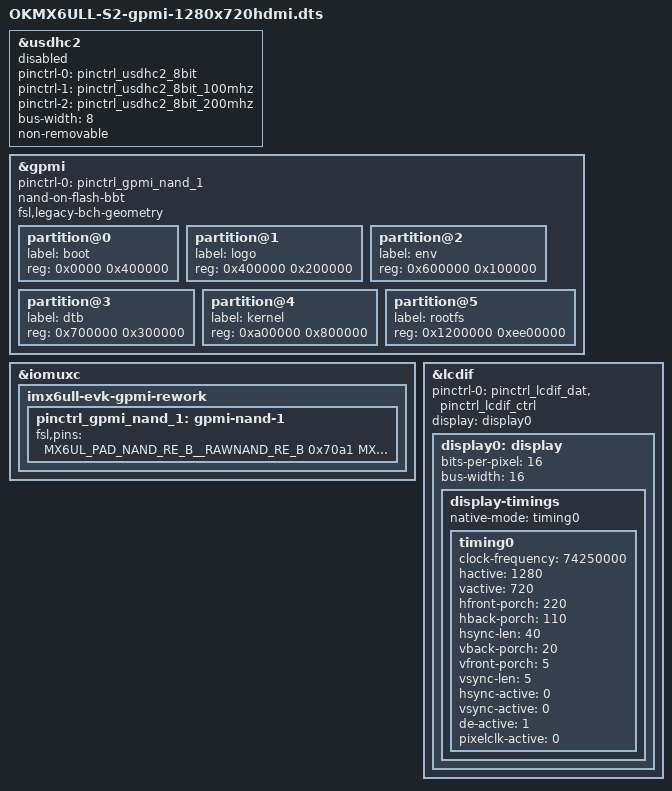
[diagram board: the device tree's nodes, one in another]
/*
 * Copyright (C) 2016 Freescale Semiconductor, Inc.
 *
 * This program is free software; you can redistribute it and/or modify
 * it under the terms of the GNU General Public License version 2 as
 * published by the Free Software Foundation.
 */

#include "imx6ull-14x14-evk.dts"

&usdhc2 {
	pinctrl-names = "default", "state_100mhz", "state_200mhz";
	pinctrl-0 = <&pinctrl_usdhc2_8bit>;
	pinctrl-1 = <&pinctrl_usdhc2_8bit_100mhz>;
	pinctrl-2 = <&pinctrl_usdhc2_8bit_200mhz>;
	bus-width = <8>;
	non-removable;
	status = "disable";
};

&gpmi {
	pinctrl-names = "default";
	pinctrl-0 = <&pinctrl_gpmi_nand_1>;
    nand-on-flash-bbt;
    fsl,legacy-bch-geometry;
	status = "okay";
    partition@0{
        label = "boot";
        reg = <0x0000 0x400000>; /*4M*/
    };
    partition@1{
        label = "logo";
        reg = <0x400000 0x200000>; /*2M*/
    };
    partition@2{
        label = "env";
        reg = <0x600000 0x100000>; /*1M*/
    };
    partition@3{
        label = "dtb";
        reg = <0x700000 0x300000>; /*3M*/
    };
    partition@4{
        label = "kernel";
        reg = <0xa00000 0x800000>; /*8M*/
    };
    partition@5{
        label = "rootfs";
        reg = <0x1200000 0xee00000>;
     };
};

&iomuxc {
	imx6ull-evk-gpmi-rework {
		pinctrl_gpmi_nand_1: gpmi-nand-1 {
			fsl,pins = <
                		MX6UL_PAD_NAND_RE_B__RAWNAND_RE_B 0x70a1
               			MX6UL_PAD_NAND_WE_B__RAWNAND_WE_B 0x70a1
          			MX6UL_PAD_NAND_DATA00__RAWNAND_DATA00 0x70a1
                		MX6UL_PAD_NAND_DATA01__RAWNAND_DATA01 0x70a1
                		MX6UL_PAD_NAND_DATA02__RAWNAND_DATA02 0x70a1
                		MX6UL_PAD_NAND_DATA03__RAWNAND_DATA03 0x70a1
                		MX6UL_PAD_NAND_DATA04__RAWNAND_DATA04 0x70a1
                		MX6UL_PAD_NAND_DATA05__RAWNAND_DATA05 0x70a1
                		MX6UL_PAD_NAND_DATA06__RAWNAND_DATA06 0x70a1
                		MX6UL_PAD_NAND_DATA07__RAWNAND_DATA07 0x70a1
                		MX6UL_PAD_NAND_ALE__RAWNAND_ALE 0x70a1
                		MX6UL_PAD_NAND_WP_B__RAWNAND_WP_B 0x70a1
                		MX6UL_PAD_NAND_READY_B__RAWNAND_READY_B 0x7099
                		MX6UL_PAD_NAND_CE0_B__RAWNAND_CE0_B 0x70a1
                		MX6UL_PAD_NAND_CLE__RAWNAND_CLE 0x70a1
			>;
		};
	};
};
&lcdif {
	pinctrl-names = "default";
	pinctrl-0 = <&pinctrl_lcdif_dat
		     &pinctrl_lcdif_ctrl
		  /* &pinctrl_lcdif_reset*/>;
	display = <&display0>;
	status = "okay";

	display0: display {
		bits-per-pixel = <16>;
		bus-width = <16>;

		display-timings {
			native-mode = <&timing0>;
			timing0: timing0 {
			clock-frequency = <74250000>;
			hactive = <1280>;
			vactive = <720>;
			hfront-porch = <220>;
			hback-porch = <110>;
			hsync-len = <40>;
			vback-porch = <20>;
			vfront-porch = <5>;
			vsync-len = <5>;

			hsync-active = <0>;
			vsync-active = <0>;
			de-active = <1>;
			pixelclk-active = <0>;
			};
		};
	};
};

